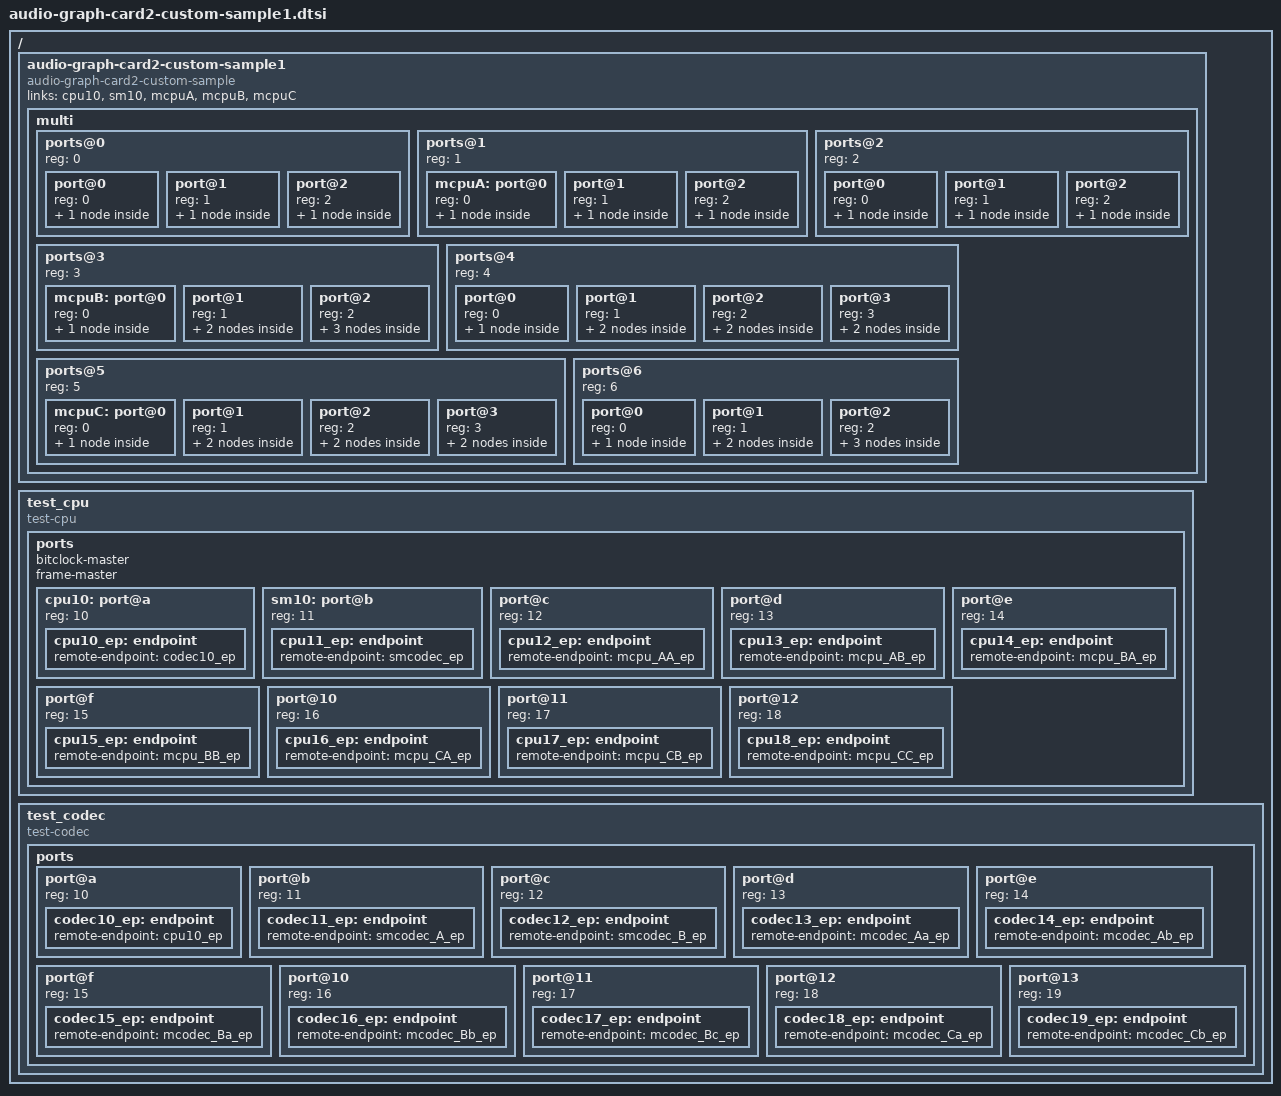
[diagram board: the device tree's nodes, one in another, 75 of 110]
// SPDX-License-Identifier: GPL-2.0
/*
 * audio-graph-card2-custom-sample1.dtsi
 *
 * Copyright (C) 2020 Renesas Electronics Corp.
 * Copyright (C) 2020 Kuninori Morimoto <kuninori.morimoto.gx@renesas.com>
 *
 * This sample indicates how to use audio-graph-card2 and its
 * custom driver. "audio-graph-card2-custom-sample" is the custome driver
 * which is using audio-graph-card2.
 *
 * You can easily use this sample by adding below line on your DT file,
 * and add new CONFIG to your .config.
 *
 *	#include "../../../../../sound/soc/generic/audio-graph-card2-custom-sample1.dtsi"
 *
 *	CONFIG_SND_AUDIO_GRAPH_CARD2
 *	CONFIG_SND_AUDIO_GRAPH_CARD2_CUSTOM_SAMPLE
 *	CONFIG_SND_TEST_COMPONENT
 *
 *
 * You can indicate more detail each device behavior as debug if you modify
 * "compatible" on each test-component. see below
 *
 *	test_cpu {
 *	-	compatible = "test-cpu";
 *	+	compatible = "test-cpu-verbose";
 *		...
 *	};
 *
 *	test_codec {
 *	-	compatible = "test-codec";
 *	+	compatible = "test-codec-verbose";
 *		...
 *	};
 *
 *
 * Below sample doesn't use "format" property,
 * because test-component driver (test-cpu/test-codec) is supporting
 * snd_soc_dai_ops :: .auto_selectable_formats.
 * see
 *	snd_soc_runtime_get_dai_fmt()
 *	linux/sound/soc/generic/test-component.c :: test_dai_formats
 */
/ {
	audio-graph-card2-custom-sample1 {
		/*
		 * You can use audio-graph-card2 directly by using
		 *
		 * compatible = "audio-graph-card2";
		 */
		compatible = "audio-graph-card2-custom-sample";

		/*
		 * @ : used at links
		 */
		links = <
			/*
			 *
			 * [Normal]
			 *
			 *	     <cpu10>
			 *	cpu10 <-@-----> codec10
			 */
			 &cpu10 /* CPU side only */

			/*
			 * [Semi-Multi]
			 *
			 * CPU:Codec = 1:N
			 *
			 *	      <sm10>	+-+
			 *	cpu11 <--@----->| |-> codec11
			 *			| |-> codec12
			 *			+-+
			 */
			&sm10 /* CPU side only */

			/*
			 * [Multi-CPU/Codec-A]
			 *
			 *		 +-+ <mcpuA>	+-+
			 *	cpu12 <--| |<---@------>| |-> codec13
			 *	cpu13 <--| |		| |-> codec14
			 *		 +-+		+-+
			 */
			&mcpuA /* CPU side only */

			/*
			 * [Multi-CPU/Codec-B]
			 *
			 *		 +-+ <mcpuB>	+-+
			 *		 | |<---@------>| |
			 *		 | |		| |
			 *	cpu14 <--| |<---------->| |-> codec15
			 *	cpu15 <--| |<---+------>| |-> codec16
			 *		 +-+	\------>| |-> codec17
			 *				+-+
			 */
			&mcpuB /* CPU side only */

			/*
			 * [Multi-CPU/Codec-C]
			 *
			 *		+-+ <mcpuC>	+-+
			 *		| |<---@------->| |
			 *		| |		| |
			 *	cpu16 <-| |<----------->| |-> codec18
			 *	cpu17 <-| |<-----+----->| |-> codec19
			 *	cpu18 <-| |<----/	+-+
			 *		+-+
			 */
			&mcpuC /* CPU side only */
		>;

		multi {
			#address-cells = <1>;
			#size-cells = <0>;

			/*
			 * [Semi-Multi]
			 *
			 *	      <sm10>	+---+
			 *	cpu11 <--@----->|X A|-> codec11
			 *			|  B|-> codec12
			 *			+---+
			 */
			ports@0 {
				reg = <0>;
				#address-cells = <1>;
				#size-cells = <0>;
				port@0 { reg = <0>; smcodec_ep:   endpoint { remote-endpoint = <&cpu11_ep>;   };};/* (X) to pair */
				port@1 { reg = <1>; smcodec_A_ep: endpoint { remote-endpoint = <&codec11_ep>; };};/* (A) Multi Element */
				port@2 { reg = <2>; smcodec_B_ep: endpoint { remote-endpoint = <&codec12_ep>; };};/* (B) Multi Element */
			};

			/*
			 * [Multi-CPU-A]
			 *
			 *		+---+ <mcpuA>	+---+
			 *	cpu12 <-|A X|<---@----->|x a|-> codec13
			 *	cpu13 <-|B  |		|  b|-> codec14
			 *		+---+		+---+
			 */
			ports@1 {
				reg = <1>;
				#address-cells = <1>;
				#size-cells = <0>;
			mcpuA:	port@0 { reg = <0>; mcpu_A_ep:  endpoint { remote-endpoint = <&mcodec_A_ep>; };}; /* (X) to pair */
				port@1 { reg = <1>; mcpu_AA_ep: endpoint { remote-endpoint = <&cpu12_ep>;    };}; /* (A) Multi Element */
				port@2 { reg = <2>; mcpu_AB_ep: endpoint { remote-endpoint = <&cpu13_ep>;    };}; /* (B) Multi Element */
			};

			/*
			 * [Multi-Codec-A]
			 *
			 *		+---+ <mcpuA>	+---+
			 *	cpu12 <-|A X|<-@------->|x a|-> codec13
			 *	cpu13 <-|B  |		|  b|-> codec14
			 *		+---+		+---+
			 */
			ports@2 {
				reg = <2>;
				#address-cells = <1>;
				#size-cells = <0>;
				port@0 { reg = <0>; mcodec_A_ep:  endpoint { remote-endpoint = <&mcpu_A_ep>;  };}; /* (x) to pair */
				port@1 { reg = <1>; mcodec_Aa_ep: endpoint { remote-endpoint = <&codec13_ep>; };}; /* (a) Multi Element */
				port@2 { reg = <2>; mcodec_Ab_ep: endpoint { remote-endpoint = <&codec14_ep>; };}; /* (b) Multi Element */
			};

			/*
			 * [Multi-CPU-B]
			 *
			 *		+---+ <mcpuB>	+---+
			 *		|  X|<---@----->|x  |
			 *		|   |		|   |
			 *	cpu14 <-|A 1|<--------->|3 a|-> codec15
			 *	cpu15 <-|B 2|<---+----->|4 b|-> codec16
			 *		+---+	  \---->|5 c|-> codec17
			 *				+---+
			 */
			ports@3 {
				reg = <3>;
				#address-cells = <1>;
				#size-cells = <0>;
			mcpuB:	port@0 {
					reg = <0>;
					mcpu_BX_ep:     endpoint { remote-endpoint = <&mcodec_Bx_ep>; }; /* (X) to pair */
				};
				port@1 {
					#address-cells = <1>;
					#size-cells = <0>;
					reg = <1>;
					mcpu_BA_ep:   endpoint@0 { reg = <0>; remote-endpoint = <&cpu14_ep>;     }; /* (A) Multi Element */
					mcpu_B1_ep:   endpoint@1 { reg = <1>; remote-endpoint = <&mcodec_B3_ep>; }; /* (1) connected Codec */
				};
				port@2 {
					#address-cells = <1>;
					#size-cells = <0>;
					reg = <2>;
					mcpu_BB_ep:   endpoint@0 { reg = <0>; remote-endpoint = <&cpu15_ep>;     }; /* (B) Multi Element */
					mcpu_B2_0_ep: endpoint@1 { reg = <1>; remote-endpoint = <&mcodec_B4_ep>; }; /* (2) connected Codec */
					mcpu_B2_1_ep: endpoint@2 { reg = <2>; remote-endpoint = <&mcodec_B5_ep>; }; /* (2) connected Codec */
				};
			};

			/*
			 * [Multi-Codec-B]
			 *
			 *		+---+ <mcpuB>	+---+
			 *		|  X|<-@------->|x  |
			 *		|   |		|   |
			 *	cpu14 <-|A 1|<--------->|3 a|-> codec15
			 *	cpu15 <-|B 2|<---+----->|4 b|-> codec16
			 *		+---+	  \---->|5 c|-> codec17
			 *				+---+
			 */
			ports@4 {
				reg = <4>;
				#address-cells = <1>;
				#size-cells = <0>;
				port@0 {
					reg = <0>;
					mcodec_Bx_ep:   endpoint { remote-endpoint = <&mcpu_BX_ep>;  }; /* (x) to pair */
				};
				port@1 {
					#address-cells = <1>;
					#size-cells = <0>;
					reg = <1>;
					mcodec_Ba_ep: endpoint@0 { reg = <0>; remote-endpoint = <&codec15_ep>; }; /* (a) Multi Element */
					mcodec_B3_ep: endpoint@1 { reg = <1>; remote-endpoint = <&mcpu_B1_ep>; }; /* (3) connected CPU */
				};
				port@2 {
					#address-cells = <1>;
					#size-cells = <0>;
					reg = <2>;
					mcodec_Bb_ep: endpoint@0 { reg = <0>; remote-endpoint = <&codec16_ep>;  }; /* (b) Multi Element */
					mcodec_B4_ep: endpoint@1 { reg = <1>; remote-endpoint = <&mcpu_B2_0_ep>;}; /* (4) connected CPU */
				};
				port@3 {
					#address-cells = <1>;
					#size-cells = <0>;
					reg = <3>;
					mcodec_Bc_ep: endpoint@0 { reg = <0>; remote-endpoint = <&codec17_ep>;  }; /* (c) Multi Element */
					mcodec_B5_ep: endpoint@1 { reg = <1>; remote-endpoint = <&mcpu_B2_1_ep>;}; /* (5) connected CPU */
				};
			};

			/*
			 * [Multi-CPU-C]
			 *
			 *		+---+ <mcpuC>	+---+
			 *		|  X|<-@------->|x  |
			 *		|   |		|   |
			 *	cpu16 <-|A 1|<--------->|4 a|-> codec18
			 *	cpu17 <-|B 2|<-----+--->|5 b|-> codec19
			 *	cpu18 <-|C 3|<----/	+---+
			 *		+---+
			 */
			ports@5 {
				reg = <5>;
				#address-cells = <1>;
				#size-cells = <0>;
			mcpuC:	port@0 {
					reg = <0>;
					mcpu_CX_ep:   endpoint { remote-endpoint = <&mcodec_Cx_ep>; }; /* (X) to pair */
				};
				port@1 {
					#address-cells = <1>;
					#size-cells = <0>;
					reg = <1>;
					mcpu_CA_ep: endpoint@0 { reg = <0>; remote-endpoint = <&cpu16_ep>;     }; /* (A) Multi Element */
					mcpu_C1_ep: endpoint@1 { reg = <1>; remote-endpoint = <&mcodec_C4_ep>; }; /* (1) connected Codec */
				};
				port@2 {
					#address-cells = <1>;
					#size-cells = <0>;
					reg = <2>;
					mcpu_CB_ep: endpoint@0 { reg = <0>; remote-endpoint = <&cpu17_ep>;       }; /* (B) Multi Element */
					mcpu_C2_ep: endpoint@1 { reg = <1>; remote-endpoint = <&mcodec_C5_0_ep>; }; /* (2) connected Codec */
				};
				port@3 {
					#address-cells = <1>;
					#size-cells = <0>;
					reg = <3>;
					mcpu_CC_ep: endpoint@0 { reg = <0>; remote-endpoint = <&cpu18_ep>;       }; /* (C) Multi Element */
					mcpu_C3_ep: endpoint@1 { reg = <1>; remote-endpoint = <&mcodec_C5_1_ep>; }; /* (3) connected Codec */
				};
			};

			/*
			 * [Multi-Codec-C]
			 *
			 *		+---+ <mcpuC>	+---+
			 *		|  X|<-@------->|x  |
			 *		|   |		|   |
			 *	cpu16 <-|A 1|<--------->|4 a|-> codec18
			 *	cpu17 <-|B 2|<-----+--->|5 b|-> codec19
			 *	cpu18 <-|C 3|<----/	+---+
			 *		+---+
			 */
			ports@6 {
				reg = <6>;
				#address-cells = <1>;
				#size-cells = <0>;
				port@0 {
					reg = <0>;
					mcodec_Cx_ep: endpoint { remote-endpoint = <&mcpu_CX_ep>;  }; /* (x) to pair */
				};
				port@1 {
					#address-cells = <1>;
					#size-cells = <0>;
					reg = <1>;
					mcodec_Ca_ep: endpoint@0 { reg = <0>; remote-endpoint = <&codec18_ep>; }; /* (a) Multi Element */
					mcodec_C4_ep: endpoint@1 { reg = <1>; remote-endpoint = <&mcpu_C1_ep>; }; /* (4) connected CPU */
				};
				port@2 {
					#address-cells = <1>;
					#size-cells = <0>;
					reg = <2>;
					mcodec_Cb_ep:   endpoint@0 { reg = <0>; remote-endpoint = <&codec19_ep>; }; /* (b) Multi Element */
					mcodec_C5_0_ep: endpoint@1 { reg = <1>; remote-endpoint = <&mcpu_C2_ep>; }; /* (5) connected CPU */
					mcodec_C5_1_ep: endpoint@2 { reg = <2>; remote-endpoint = <&mcpu_C3_ep>; }; /* (5) connected CPU */
				};
			};
		};
	};

	test_cpu {
		/*
		 * update compatible to indicate more detail behaviour
		 * if you want. see test-compatible for more detail.
		 *
		 * ex)
		 *	- compatible = "test-cpu";
		 *	+ compatible = "test-cpu-verbose";
		 */
		compatible = "test-cpu";
		ports {
			#address-cells = <1>;
			#size-cells = <0>;

			bitclock-master;
			frame-master;

				/* [Normal] */
			cpu10:	port@a  { reg = <10>; cpu10_ep: endpoint { remote-endpoint = <&codec10_ep>; }; };
				/* [Semi-Multi] */
			sm10:	port@b  { reg = <11>; cpu11_ep: endpoint { remote-endpoint = <&smcodec_ep>; }; };
				/* [Multi-CPU-A] */
				port@c  { reg = <12>; cpu12_ep: endpoint { remote-endpoint = <&mcpu_AA_ep>; }; };
				port@d  { reg = <13>; cpu13_ep: endpoint { remote-endpoint = <&mcpu_AB_ep>; }; };
				/* [Multi-CPU-B] */
				port@e  { reg = <14>; cpu14_ep: endpoint { remote-endpoint = <&mcpu_BA_ep>; }; };
				port@f  { reg = <15>; cpu15_ep: endpoint { remote-endpoint = <&mcpu_BB_ep>; }; };
				/* [Multi-CPU-C] */
				port@10 { reg = <16>; cpu16_ep: endpoint { remote-endpoint = <&mcpu_CA_ep>; }; };
				port@11 { reg = <17>; cpu17_ep: endpoint { remote-endpoint = <&mcpu_CB_ep>; }; };
				port@12 { reg = <18>; cpu18_ep: endpoint { remote-endpoint = <&mcpu_CC_ep>; }; };
		};
	};

	test_codec {
		/*
		 * update compatible to indicate more detail behaviour
		 * if you want. see test-compatible for more detail.
		 *
		 * ex)
		 *	- compatible = "test-codec";
		 *	+ compatible = "test-codec-verbose";
		 */
		compatible = "test-codec";
		ports {
			#address-cells = <1>;
			#size-cells = <0>;

			/* [Normal] */
			port@a  { reg = <10>; codec10_ep: endpoint { remote-endpoint = <&cpu10_ep>;     }; };
			/* [Semi-Multi] */
			port@b  { reg = <11>; codec11_ep: endpoint { remote-endpoint = <&smcodec_A_ep>; }; };
			port@c  { reg = <12>; codec12_ep: endpoint { remote-endpoint = <&smcodec_B_ep>; }; };
			/* [Multi-Codec-0] */
			port@d  { reg = <13>; codec13_ep: endpoint { remote-endpoint = <&mcodec_Aa_ep>; }; };
			port@e  { reg = <14>; codec14_ep: endpoint { remote-endpoint = <&mcodec_Ab_ep>; }; };
			/* [Multi-Codec-1] */
			port@f  { reg = <15>; codec15_ep: endpoint { remote-endpoint = <&mcodec_Ba_ep>; }; };
			port@10 { reg = <16>; codec16_ep: endpoint { remote-endpoint = <&mcodec_Bb_ep>; }; };
			port@11 { reg = <17>; codec17_ep: endpoint { remote-endpoint = <&mcodec_Bc_ep>; }; };
			/* [Multi-Codec-2] */
			port@12 { reg = <18>; codec18_ep: endpoint { remote-endpoint = <&mcodec_Ca_ep>; }; };
			port@13 { reg = <19>; codec19_ep: endpoint { remote-endpoint = <&mcodec_Cb_ep>; }; };
		};
	};
};
